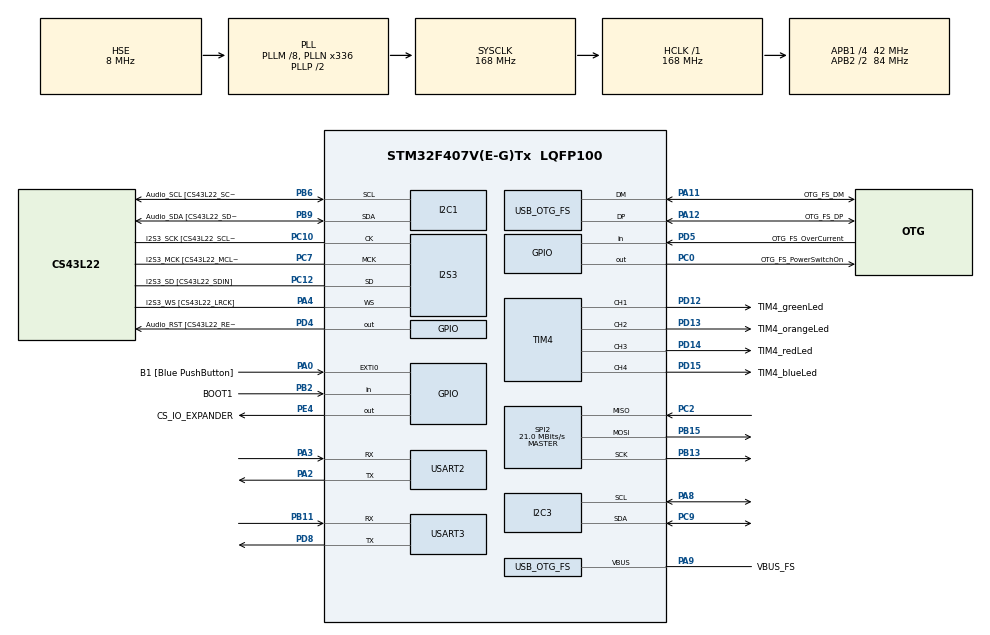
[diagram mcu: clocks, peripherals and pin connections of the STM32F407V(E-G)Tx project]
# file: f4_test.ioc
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Dma.Request0=USART3_RX
Dma.Request1=SPI3_TX
Dma.SPI3_TX.1.Direction=DMA_MEMORY_TO_PERIPH
Dma.SPI3_TX.1.FIFOMode=DMA_FIFOMODE_DISABLE
Dma.SPI3_TX.1.Instance=DMA1_Stream5
Dma.SPI3_TX.1.MemDataAlignment=DMA_MDATAALIGN_HALFWORD
Dma.SPI3_TX.1.MemInc=DMA_MINC_ENABLE
Dma.SPI3_TX.1.Mode=DMA_CIRCULAR
Dma.SPI3_TX.1.PeriphDataAlignment=DMA_PDATAALIGN_HALFWORD
Dma.SPI3_TX.1.PeriphInc=DMA_PINC_DISABLE
Dma.SPI3_TX.1.Priority=DMA_PRIORITY_VERY_HIGH
Dma.USART3_RX.0.Direction=DMA_PERIPH_TO_MEMORY
Dma.USART3_RX.0.FIFOMode=DMA_FIFOMODE_DISABLE
Dma.USART3_RX.0.Instance=DMA1_Stream1
Dma.USART3_RX.0.MemDataAlignment=DMA_MDATAALIGN_BYTE
Dma.USART3_RX.0.MemInc=DMA_MINC_ENABLE
Dma.USART3_RX.0.Mode=DMA_CIRCULAR
Dma.USART3_RX.0.PeriphDataAlignment=DMA_PDATAALIGN_BYTE
Dma.USART3_RX.0.PeriphInc=DMA_PINC_DISABLE
Dma.USART3_RX.0.Priority=DMA_PRIORITY_LOW
I2S3.AudioFreq=I2S_AUDIOFREQ_32K
I2S3.AudioFreq-Half_Duplex_Master=I2S_AUDIOFREQ_96K
I2S3.ErrorAudioFreq=-2.34 %
I2S3.ErrorAudioFreq-Half_Duplex_Master=0.8 %
I2S3.FullDuplexMode=I2S_FULLDUPLEXMODE_DISABLE
I2S3.Instance=SPI$Index
I2S3.RealAudioFreq=31.25 KHz
I2S3.RealAudioFreq-Half_Duplex_Master=96.774 KHz
I2S3.VirtualMode=I2S_MODE_MASTER
Mcu.Family=STM32F4
Mcu.Name=STM32F407V(E-G)Tx
Mcu.Package=LQFP100
NVIC.DMA1_Stream1_IRQn=true\:0\:0\:false\:false\:true\:false
NVIC.DMA1_Stream5_IRQn=true\:0\:0\:false\:false\:true\:false
NVIC.OTG_FS_IRQn=true\:0\:0\:false\:false\:true\:true
NVIC.PriorityGroup=NVIC_PRIORITYGROUP_0
NVIC.TIM5_IRQn=true\:0\:0\:false\:false\:true\:true
NVIC.TIM6_DAC_IRQn=true\:0\:0\:false\:false\:true\:true
NVIC.TIM8_TRG_COM_TIM14_IRQn=true\:0\:0\:false\:false\:true\:true
NVIC.USART2_IRQn=true\:0\:0\:false\:false\:true\:true
NVIC.USART3_IRQn=true\:0\:0\:false\:false\:true\:true
PA0-WKUP.GPIO_Label=B1 [Blue PushButton]
PA0-WKUP.GPIO_ModeDefaultEXTI=GPIO_MODE_EVT_RISING
PA0-WKUP.GPIO_PuPd=GPIO_NOPULL
PA0-WKUP.Signal=GPXTI0
PA10.GPIO_Label=OTG_FS_ID
PA10.GPIO_Mode=GPIO_MODE_AF_PP
PA10.GPIO_PuPd=GPIO_NOPULL
PA10.GPIO_Speed=GPIO_SPEED_FREQ_LOW
PA10.Signal=USB_OTG_FS_ID
PA11.GPIO_Label=OTG_FS_DM
PA11.GPIO_Mode=GPIO_MODE_AF_PP
PA11.GPIO_PuPd=GPIO_NOPULL
PA11.GPIO_Speed=GPIO_SPEED_FREQ_LOW
PA11.Mode=Device_Only
PA11.Signal=USB_OTG_FS_DM
PA12.GPIO_Label=OTG_FS_DP
PA12.GPIO_Mode=GPIO_MODE_AF_PP
PA12.GPIO_PuPd=GPIO_NOPULL
PA12.GPIO_Speed=GPIO_SPEED_FREQ_LOW
PA12.Mode=Device_Only
PA12.Signal=USB_OTG_FS_DP
PA13.GPIO_Label=SWDIO
PA13.Mode=Serial_Wire
PA13.Signal=SYS_JTMS-SWDIO
PA14.GPIO_Label=SWCLK
PA14.Mode=Serial_Wire
PA14.Signal=SYS_JTCK-SWCLK
PA2.Mode=Asynchronous
PA2.Signal=USART2_TX
PA3.Mode=Asynchronous
PA3.Signal=USART2_RX
PA4.GPIO_Label=I2S3_WS [CS43L22_LRCK]
PA4.GPIO_Mode=GPIO_MODE_AF_PP
PA4.GPIO_PuPd=GPIO_NOPULL
PA4.GPIO_Speed=GPIO_SPEED_FREQ_LOW
PA4.Mode=Half_Duplex_Master
PA4.Signal=I2S3_WS
PA8.Mode=I2C
PA8.Signal=I2C3_SCL
PA9.GPIO_Label=VBUS_FS
PA9.GPIO_Mode=GPIO_MODE_INPUT
PA9.GPIO_PuPd=GPIO_NOPULL
PA9.Mode=Activate_VBUS
PA9.Signal=USB_OTG_FS_VBUS
PB10.GPIO_Label=CLK_IN [MP45DT02_CLK]
PB10.GPIO_Mode=GPIO_MODE_AF_PP
PB10.GPIO_PuPd=GPIO_NOPULL
PB10.GPIO_Speed=GPIO_SPEED_FREQ_LOW
PB10.Signal=I2S2_CK
PB11.Mode=Asynchronous
PB11.Signal=USART3_RX
PB13.Mode=Full_Duplex_Master
PB13.Signal=SPI2_SCK
PB15.Mode=Full_Duplex_Master
PB15.Signal=SPI2_MOSI
PB2.GPIO_Label=BOOT1
PB2.GPIO_Mode=GPIO_MODE_INPUT
PB2.GPIO_PuPd=GPIO_NOPULL
PB2.Signal=GPIO_Input
PB3.GPIO_Label=SWO
PB3.Signal=SYS_JTDO-SWO
PB6.GPIO_Label=Audio_SCL [CS43L22_SCL]
PB6.GPIO_Mode=GPIO_MODE_AF_OD
PB6.GPIO_PuPd=GPIO_NOPULL
PB6.GPIO_Speed=GPIO_SPEED_FREQ_LOW
PB6.Mode=I2C
PB6.Signal=I2C1_SCL
PB9.GPIO_Label=Audio_SDA [CS43L22_SDA]
PB9.GPIO_Mode=GPIO_MODE_AF_OD
PB9.GPIO_PuPd=GPIO_NOPULL
PB9.GPIO_Speed=GPIO_SPEED_FREQ_LOW
PB9.Mode=I2C
PB9.Signal=I2C1_SDA
PC0.GPIO_Label=OTG_FS_PowerSwitchOn
PC0.GPIO_PuPd=GPIO_NOPULL
PC0.GPIO_Speed=GPIO_SPEED_FREQ_LOW
PC0.PinState=GPIO_PIN_SET
PC0.Signal=GPIO_Output
PC10.GPIO_Label=I2S3_SCK [CS43L22_SCLK]
PC10.GPIO_Mode=GPIO_MODE_AF_PP
PC10.GPIO_PuPd=GPIO_NOPULL
PC10.GPIO_Speed=GPIO_SPEED_FREQ_LOW
PC10.Mode=Half_Duplex_Master
PC10.Signal=I2S3_CK
PC12.GPIO_Label=I2S3_SD [CS43L22_SDIN]
PC12.GPIO_Mode=GPIO_MODE_AF_PP
PC12.GPIO_PuPd=GPIO_NOPULL
PC12.GPIO_Speed=GPIO_SPEED_FREQ_LOW
PC12.Mode=Half_Duplex_Master
PC12.Signal=I2S3_SD
PC14-OSC32_IN.GPIO_Label=PC14-OSC32_IN
PC14-OSC32_IN.Mode=LSE-External-Oscillator
PC14-OSC32_IN.Signal=RCC_OSC32_IN
PC15-OSC32_OUT.GPIO_Label=PC15-OSC32_OUT
PC15-OSC32_OUT.Mode=LSE-External-Oscillator
PC15-OSC32_OUT.Signal=RCC_OSC32_OUT
PC2.Mode=Full_Duplex_Master
PC2.Signal=SPI2_MISO
PC3.GPIO_Label=PDM_OUT [MP45DT02_DOUT]
PC3.GPIO_Mode=GPIO_MODE_AF_PP
PC3.GPIO_PuPd=GPIO_NOPULL
PC3.GPIO_Speed=GPIO_SPEED_FREQ_LOW
PC3.Signal=I2S2_SD
PC7.GPIO_Label=I2S3_MCK [CS43L22_MCLK]
PC7.GPIO_Mode=GPIO_MODE_AF_PP
PC7.GPIO_PuPd=GPIO_NOPULL
PC7.GPIO_Speed=GPIO_SPEED_FREQ_LOW
PC7.Mode=Master_Clock_Activated
PC7.Signal=I2S3_MCK
PC9.Mode=I2C
PC9.Signal=I2C3_SDA
PD12.GPIO_Label=TIM4_greenLed
PD12.Signal=S_TIM4_CH1
PD13.GPIO_Label=TIM4_orangeLed
PD13.Signal=S_TIM4_CH2
PD14.GPIO_Label=TIM4_redLed
PD14.Signal=S_TIM4_CH3
PD15.GPIO_Label=TIM4_blueLed
PD15.Signal=S_TIM4_CH4
PD4.GPIO_Label=Audio_RST [CS43L22_RESET]
PD4.GPIO_PuPd=GPIO_NOPULL
PD4.GPIO_Speed=GPIO_SPEED_FREQ_LOW
PD4.Signal=GPIO_Output
PD5.GPIO_Label=OTG_FS_OverCurrent
PD5.GPIO_Mode=GPIO_MODE_INPUT
PD5.GPIO_PuPd=GPIO_NOPULL
PD5.Signal=GPIO_Input
PD8.Mode=Asynchronous
PD8.Signal=USART3_TX
PE4.GPIO_Label=CS_IO_EXPANDER
PE4.Signal=GPIO_Output
PH0-OSC_IN.GPIO_Label=PH0-OSC_IN
PH0-OSC_IN.Mode=HSE-External-Oscillator
PH0-OSC_IN.Signal=RCC_OSC_IN
PH1-OSC_OUT.GPIO_Label=PH1-OSC_OUT
PH1-OSC_OUT.Mode=HSE-External-Oscillator
PH1-OSC_OUT.Signal=RCC_OSC_OUT
ProjectManager.HeapSize=0x200
ProjectManager.StackSize=0x400
ProjectManager.TargetToolchain=Makefile
RCC.48MHZClocksFreq_Value=48000000
RCC.AHBFreq_Value=168000000
RCC.APB1CLKDivider=RCC_HCLK_DIV4
RCC.APB1Freq_Value=42000000
RCC.APB1TimFreq_Value=84000000
RCC.APB2CLKDivider=RCC_HCLK_DIV2
RCC.APB2Freq_Value=84000000
RCC.APB2TimFreq_Value=168000000
RCC.CortexFreq_Value=168000000
RCC.HCLKFreq_Value=168000000
RCC.HSE_VALUE=8000000
RCC.HSI_VALUE=16000000
RCC.PLLM=8
RCC.PLLN=336
RCC.PLLQ=7
RCC.SYSCLKFreq_VALUE=168000000
RCC.SYSCLKSource=RCC_SYSCLKSOURCE_PLLCLK
RCC.VCOOutputFreq_Value=336000000
SH.S_TIM4_CH1.0=TIM4_CH1,PWM Generation1 CH1
SH.S_TIM4_CH2.0=TIM4_CH2,PWM Generation2 CH2
SH.S_TIM4_CH3.0=TIM4_CH3,PWM Generation3 CH3
SH.S_TIM4_CH4.0=TIM4_CH4,PWM Generation4 CH4
SPI2.CalculateBaudRate=21.0 MBits/s
SPI2.Direction=SPI_DIRECTION_2LINES
SPI2.Mode=SPI_MODE_MASTER
SPI2.VirtualType=VM_MASTER
TIM1.Channel-Output\ Compare3\ No\ Output=TIM_CHANNEL_3
TIM12.Channel-Output\ Compare1\ No\ Output=TIM_CHANNEL_1
TIM13.Channel=TIM_CHANNEL_1
TIM2.Channel-Output\ Compare1\ No\ Output=TIM_CHANNEL_1
TIM2.Channel-Output\ Compare2\ No\ Output=TIM_CHANNEL_2
TIM2.Channel-Output\ Compare3\ No\ Output=TIM_CHANNEL_3
TIM2.Channel-Output\ Compare4\ No\ Output=TIM_CHANNEL_4
TIM3.Channel-Output\ Compare1\ No\ Output=TIM_CHANNEL_1
TIM4.Channel-PWM\ Generation1\ CH1=TIM_CHANNEL_1
TIM4.Channel-PWM\ Generation2\ CH2=TIM_CHANNEL_2
TIM4.Channel-PWM\ Generation3\ CH3=TIM_CHANNEL_3
TIM4.Channel-PWM\ Generation4\ CH4=TIM_CHANNEL_4
TIM5.Channel-Output\ Compare1\ No\ Output=TIM_CHANNEL_1
TIM8.Channel-Output\ Compare1\ No\ Output=TIM_CHANNEL_1
USART2.VirtualMode=VM_ASYNC
USART3.BaudRate=MIDI_USART_BAUD_RATE
USART3.VirtualMode=VM_ASYNC
USB_DEVICE.CLASS_NAME_FS=CDC
USB_DEVICE.VirtualMode-CDC_FS=Cdc
USB_DEVICE.VirtualModeFS=Cdc_FS
USB_OTG_FS.VirtualMode=Device_Only
VP_TIM12_VS_no_output1.Mode=Output Compare1 No Output
VP_TIM13_VS_ClockSourceINT.Mode=Enable_Timer
VP_TIM13_VS_no_output1.Mode=Output Compare1 No Output
VP_TIM14_VS_ClockSourceINT.Mode=Enable_Timer
VP_TIM1_VS_ClockSourceINT.Mode=Internal
VP_TIM1_VS_no_output3.Mode=Output Compare3 No Output
VP_TIM2_VS_ClockSourceINT.Mode=Internal
VP_TIM2_VS_no_output1.Mode=Output Compare1 No Output
VP_TIM3_VS_ClockSourceINT.Mode=Internal
VP_TIM3_VS_no_output1.Mode=Output Compare1 No Output
VP_TIM4_VS_ClockSourceINT.Mode=Internal
VP_TIM5_VS_ClockSourceINT.Mode=Internal
VP_TIM5_VS_no_output1.Mode=Output Compare1 No Output
VP_TIM6_VS_ClockSourceINT.Mode=Enable_Timer
VP_TIM7_VS_ClockSourceINT.Mode=Enable_Timer
VP_TIM8_VS_ClockSourceINT.Mode=Internal
VP_TIM8_VS_no_output1.Mode=Output Compare1 No Output
VP_USB_DEVICE_VS_USB_DEVICE_CDC_FS.Mode=CDC_FS
board=STM32F4DISCOVERY

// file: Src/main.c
/**
  ******************************************************************************
  * @file           : main.c
  * @brief          : Main program body
  ******************************************************************************
  * This notice applies to any and all portions of this file
  * that are not between comment pairs USER CODE BEGIN and
  * USER CODE END. Other portions of this file, whether
  * inserted by the user or by software development tools
  * are owned by their respective copyright owners.
  *
  * Copyright (c) 2019 STMicroelectronics International N.V.
  * All rights reserved.
  *
  * Redistribution and use in source and binary forms, with or without
  * modification, are permitted, provided that the following conditions are met:
  *
  * 1. Redistribution of source code must retain the above copyright notice,
  *    this list of conditions and the following disclaimer.
  * 2. Redistributions in binary form must reproduce the above copyright notice,
  *    this list of conditions and the following disclaimer in the documentation
  *    and/or other materials provided with the distribution.
  * 3. Neither the name of STMicroelectronics nor the names of other
  *    contributors to this software may be used to endorse or promote products
  *    derived from this software without specific written permission.
  * 4. This software, including modifications and/or derivative works of this
  *    software, must execute solely and exclusively on microcontroller or
  *    microprocessor devices manufactured by or for STMicroelectronics.
  * 5. Redistribution and use of this software other than as permitted under
  *    this license is void and will automatically terminate your rights under
  *    this license.
  *
  * THIS SOFTWARE IS PROVIDED BY STMICROELECTRONICS AND CONTRIBUTORS "AS IS"
  * AND ANY EXPRESS, IMPLIED OR STATUTORY WARRANTIES, INCLUDING, BUT NOT
  * LIMITED TO, THE IMPLIED WARRANTIES OF MERCHANTABILITY, FITNESS FOR A
  * PARTICULAR PURPOSE AND NON-INFRINGEMENT OF THIRD PARTY INTELLECTUAL PROPERTY
  * RIGHTS ARE DISCLAIMED TO THE FULLEST EXTENT PERMITTED BY LAW. IN NO EVENT
  * SHALL STMICROELECTRONICS OR CONTRIBUTORS BE LIABLE FOR ANY DIRECT, INDIRECT,
  * INCIDENTAL, SPECIAL, EXEMPLARY, OR CONSEQUENTIAL DAMAGES (INCLUDING, BUT NOT
  * LIMITED TO, PROCUREMENT OF SUBSTITUTE GOODS OR SERVICES; LOSS OF USE, DATA,
  * OR PROFITS; OR BUSINESS INTERRUPTION) HOWEVER CAUSED AND ON ANY THEORY OF
  * LIABILITY, WHETHER IN CONTRACT, STRICT LIABILITY, OR TORT (INCLUDING
  * NEGLIGENCE OR OTHERWISE) ARISING IN ANY WAY OUT OF THE USE OF THIS SOFTWARE,
  * EVEN IF ADVISED OF THE POSSIBILITY OF SUCH DAMAGE.
  *
  ******************************************************************************
  */
#include "main.h"
#include "stm32f4xx_hal.h"
#include "dma.h"
#include "i2c.h"
#include "i2s.h"
#include "spi.h"
#include "tim.h"
#include "usart.h"
#include "usb_device.h"
#include "gpio.h"

/* USER CODE BEGIN Includes */
#include "midi.h"
#include "cmd_shell.h"
#include "led.h"
/* USER CODE END Includes */

/* USER CODE BEGIN PV */
/* Private variables ---------------------------------------------------------*/

/* USER CODE END PV */

void SystemClock_Config(void);

/* USER CODE BEGIN PFP */
/* Private function prototypes -----------------------------------------------*/

/* USER CODE END PFP */

int main(void)
{

  /* MCU Configuration----------------------------------------------------------*/

  /* Reset of all peripherals, Initializes the Flash interface and the Systick. */
  HAL_Init();

  /* Configure the system clock */
  SystemClock_Config();

  /* Initialize all configured peripherals */
  MX_GPIO_Init();
  MX_DMA_Init();
  MX_I2C1_Init();
  MX_I2S3_Init();
  MX_TIM1_Init();
  MX_TIM4_Init();
  MX_TIM2_Init();
  MX_TIM3_Init();
  MX_TIM5_Init();
  MX_USART2_UART_Init();
  MX_SPI2_Init();
  MX_TIM14_Init();
  MX_TIM13_Init();
  MX_TIM12_Init();
  MX_TIM6_Init();
  MX_TIM8_Init();
  MX_TIM7_Init();
  MX_USART3_UART_Init();
  MX_USB_DEVICE_Init();
  MX_I2C3_Init();
  /* USER CODE BEGIN 2 */
  led_init();
  sinetable_init();
  LED_SET_CHANNEL(PWM_CHANNEL_RED, 999);
  cmd_shell_init();
  midi_init();
  codec_init();
  synth_init();

  LED_SET_CHANNEL(PWM_CHANNEL_RED, 0);
  /* USER CODE END 2 */

  /* Infinite loop */
  while (1)
  {

  }

}

void SystemClock_Config(void)
{

  RCC_OscInitTypeDef RCC_OscInitStruct;
  RCC_ClkInitTypeDef RCC_ClkInitStruct;
  RCC_PeriphCLKInitTypeDef PeriphClkInitStruct;

    /**Configure the main internal regulator output voltage
    */
  __HAL_RCC_PWR_CLK_ENABLE();

  __HAL_PWR_VOLTAGESCALING_CONFIG(PWR_REGULATOR_VOLTAGE_SCALE1);

    /**Initializes the CPU, AHB and APB busses clocks
    */
  RCC_OscInitStruct.OscillatorType = RCC_OSCILLATORTYPE_HSE;
  RCC_OscInitStruct.HSEState = RCC_HSE_ON;
  RCC_OscInitStruct.PLL.PLLState = RCC_PLL_ON;
  RCC_OscInitStruct.PLL.PLLSource = RCC_PLLSOURCE_HSE;
  RCC_OscInitStruct.PLL.PLLM = 8;
  RCC_OscInitStruct.PLL.PLLN = 336;
  RCC_OscInitStruct.PLL.PLLP = RCC_PLLP_DIV2;
  RCC_OscInitStruct.PLL.PLLQ = 7;
  if (HAL_RCC_OscConfig(&RCC_OscInitStruct) != HAL_OK)
  {
    _Error_Handler(__FILE__, __LINE__);
  }

    /**Initializes the CPU, AHB and APB busses clocks
    */
  RCC_ClkInitStruct.ClockType = RCC_CLOCKTYPE_HCLK|RCC_CLOCKTYPE_SYSCLK
                              |RCC_CLOCKTYPE_PCLK1|RCC_CLOCKTYPE_PCLK2;
  RCC_ClkInitStruct.SYSCLKSource = RCC_SYSCLKSOURCE_PLLCLK;
  RCC_ClkInitStruct.AHBCLKDivider = RCC_SYSCLK_DIV1;
  RCC_ClkInitStruct.APB1CLKDivider = RCC_HCLK_DIV4;
  RCC_ClkInitStruct.APB2CLKDivider = RCC_HCLK_DIV2;

  if (HAL_RCC_ClockConfig(&RCC_ClkInitStruct, FLASH_LATENCY_5) != HAL_OK)
  {
    _Error_Handler(__FILE__, __LINE__);
  }

  PeriphClkInitStruct.PeriphClockSelection = RCC_PERIPHCLK_I2S;
  PeriphClkInitStruct.PLLI2S.PLLI2SN = 192;
  PeriphClkInitStruct.PLLI2S.PLLI2SR = 2;
  if (HAL_RCCEx_PeriphCLKConfig(&PeriphClkInitStruct) != HAL_OK)
  {
    _Error_Handler(__FILE__, __LINE__);
  }

    /**Configure the Systick interrupt time
    */
  HAL_SYSTICK_Config(HAL_RCC_GetHCLKFreq()/1000);

    /**Configure the Systick
    */
  HAL_SYSTICK_CLKSourceConfig(SYSTICK_CLKSOURCE_HCLK);

  /* SysTick_IRQn interrupt configuration */
  HAL_NVIC_SetPriority(SysTick_IRQn, 0, 0);
}

void _Error_Handler(char *file, int line)
{
  while(1)
  {
  }
}

/************************ (C) COPYRIGHT STMicroelectronics *****END OF FILE****/
